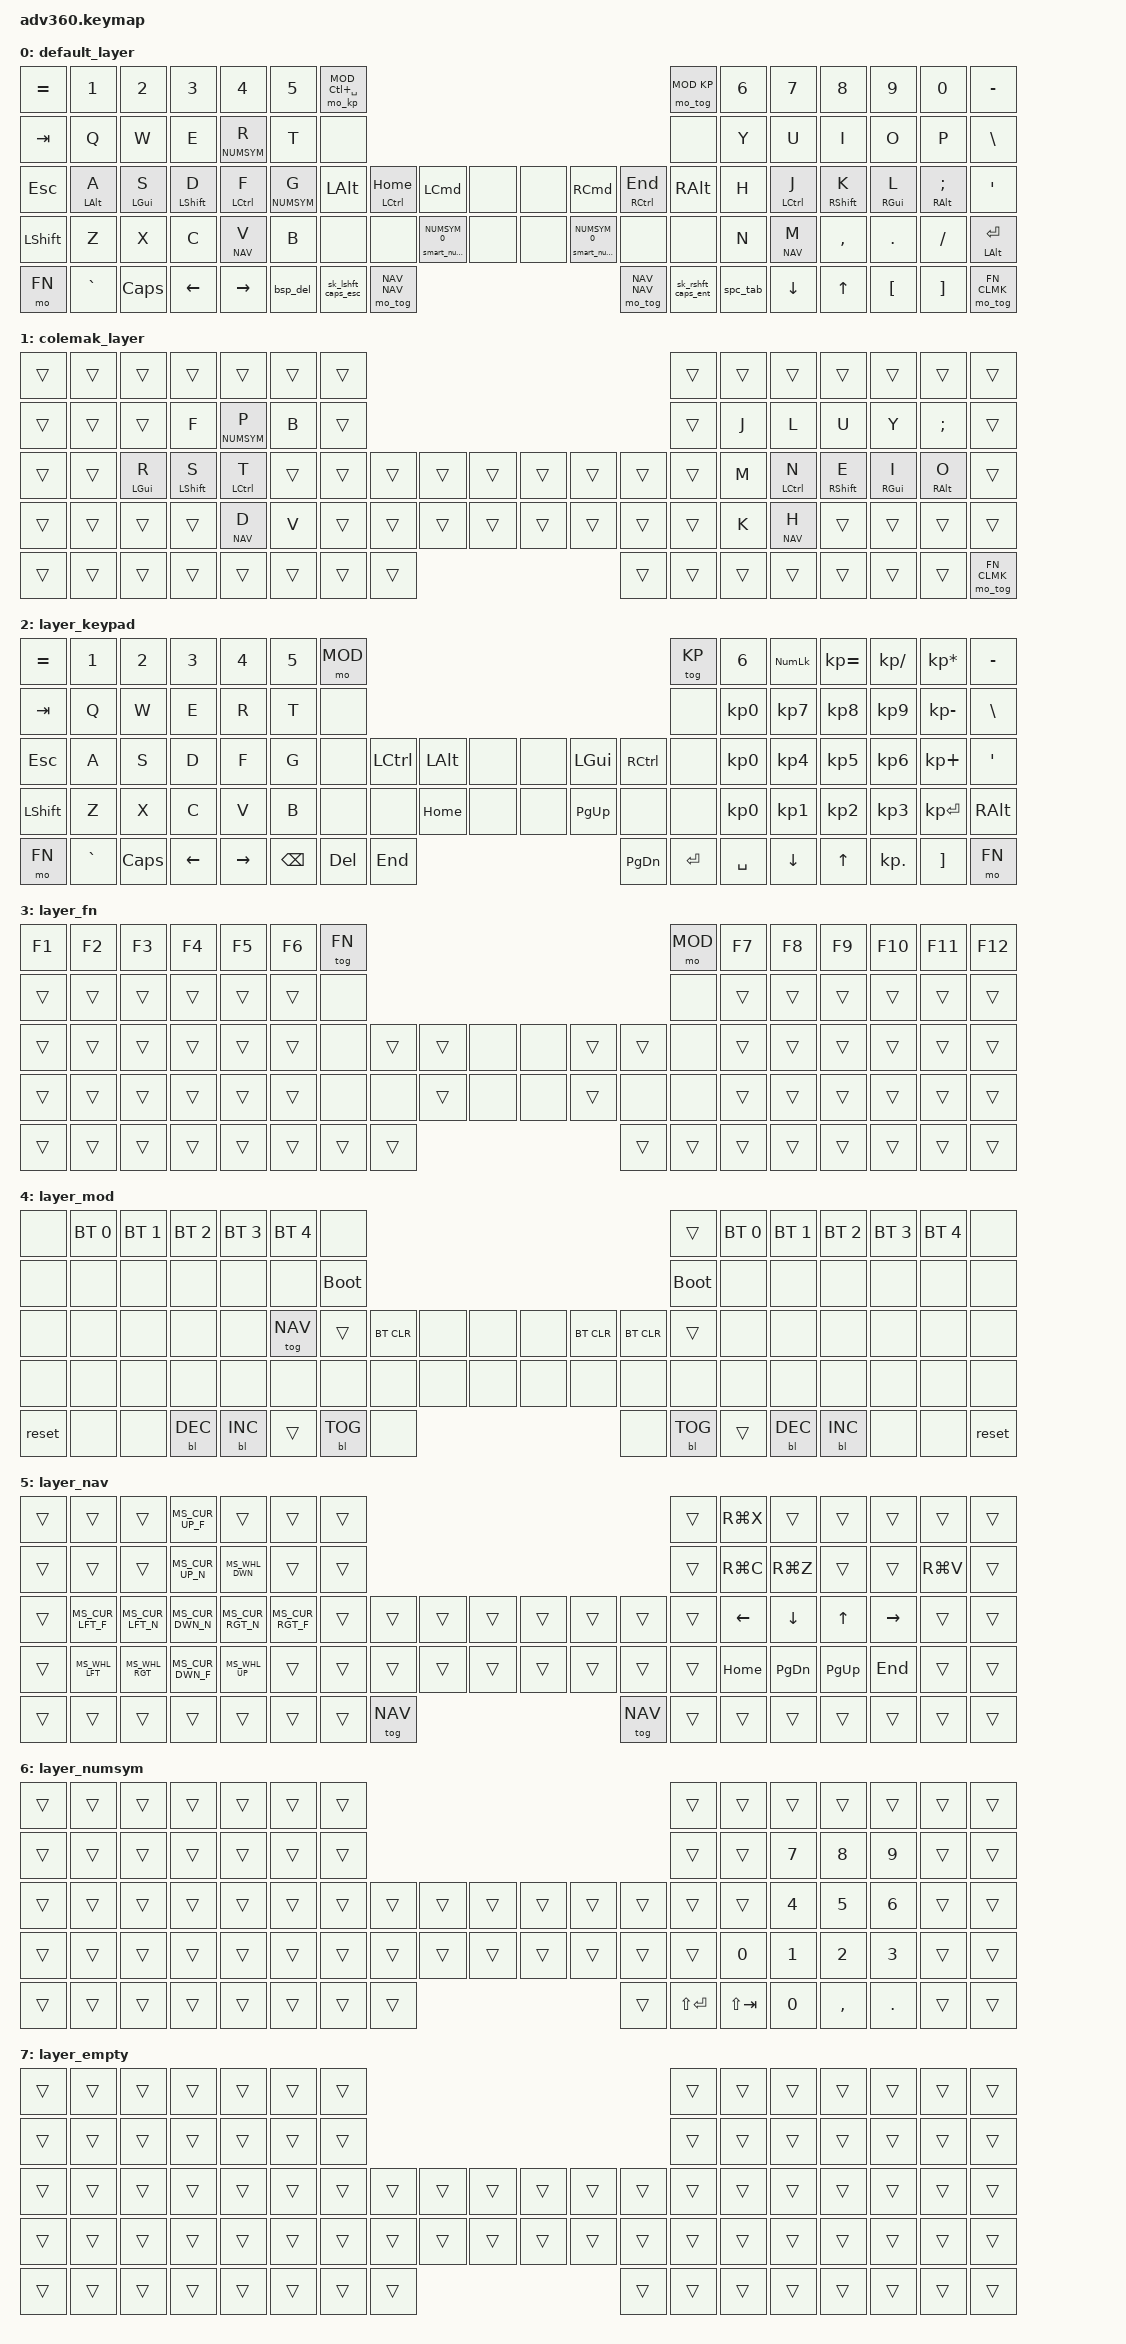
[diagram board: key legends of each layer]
#include <behaviors.dtsi>
#include <dt-bindings/zmk/keys.h>
#include <dt-bindings/zmk/bt.h>
#include <dt-bindings/zmk/outputs.h>
#include <dt-bindings/zmk/rgb.h>
#include <dt-bindings/zmk/backlight.h>

#include "./zmk-nodefree-config/helper.h"

/* definitions for mouse layer */
#include "mouse.dtsi"
 
#include "keypos_adv360.h"

#define KEYS_L LT0 LT1 LT2 LT3 LT4 LM0 LM1 LM2 LM3 LM4 LB0 LB1 LB2 LB3 LB4 LU0 LU1 LU2 LU3 // left-hand keys
#define KEYS_R RT0 RT1 RT2 RT3 RT4 RM0 RM1 RM2 RM3 RM4 RB0 RB1 RB2 RB3 RB4 RU0 RU1 RU2 RU3 // right-hand keys
#define THUMBS LH1 LH0 RH0 RH1                                       // thumb keys

#define QUICK_TAP_MS 175

ZMK_BEHAVIOR(hml, hold_tap,  // left-hand HRMs
    flavor = "balanced";
    tapping-term-ms = <280>;
    quick-tap-ms = <QUICK_TAP_MS>;
    global-quick-tap-ms = <150>;        // requires PR #1387
    bindings = <&kp>, <&kp>;
    hold-trigger-key-positions = <KEYS_R THUMBS>;
    hold-trigger-on-release;            // requires PR #1423
)

// here we use tap-unless-interrupted and not balanced because these are used for arrow keys and I want autorepeat of the arrow after waitig a while
// so the key is considered an wrrow key after the tapping-term-ms
ZMK_BEHAVIOR(hmr, hold_tap,  // right-hand HRMs
    flavor = "tap-unless-interrupted";
    tapping-term-ms = <650>;
    quick-tap-ms = <QUICK_TAP_MS>;
    global-quick-tap-ms = <150>;        // requires PR #1387
    bindings = <&kp>, <&kp>;
    hold-trigger-key-positions = <KEYS_L THUMBS>;
    hold-trigger-on-release;            // requires PR #1423
)

// replicate left-hand HRM for repeat combo
ZMK_BEHAVIOR(hml_repeat, hold_tap,
    flavor = "balanced";
    tapping-term-ms = <280>;
    quick-tap-ms = <QUICK_TAP_MS>;
    global-quick-tap-ms = <150>;
    bindings = <&kp>, <&key_repeat>;
    hold-trigger-key-positions = <KEYS_R THUMBS>;
    hold-trigger-on-release;
)

// replicate left-hand HRM for momentary layer
ZMK_BEHAVIOR(hml_ml, hold_tap,
    flavor = "balanced";
    tapping-term-ms = <280>;
    quick-tap-ms = <QUICK_TAP_MS>;
    global-quick-tap-ms = <150>;
    bindings = <&mo>, <&kp>;
    hold-trigger-key-positions = <KEYS_R THUMBS>; //?
    hold-trigger-on-release; //?
)

// replicate left-hand HRM for momentary layer
ZMK_BEHAVIOR(hmr_ml, hold_tap,
    flavor = "balanced";
    tapping-term-ms = <280>;
    quick-tap-ms = <QUICK_TAP_MS>;
    global-quick-tap-ms = <150>;
    bindings = <&mo>, <&kp>;
    hold-trigger-key-positions = <KEYS_L THUMBS>; //?
    hold-trigger-on-release; //?
)

#define ___ &trans
#define xxx &none

#define DEF 0
#define CLMK 1
#define KP 2
#define FN 3
#define MOD 4
#define NAV 5
#define NUMSYM 6

#define COMBO_SLOW 50
#define COMBO_NORM 35
#define COMBO_FAST 20

/* Sticky key settings ****************************************/ 
&sk {  // sticky-key config
    release-after-ms = <600>;  // release after 0.6s
    quick-release;             // no double capitalization when rolling keys
};

/* Sticky layer settings ****************************************/ 
&sl {
    release-after-ms = <7500>;
};

/* Caps word and Num word functionality *************************************************/ 
&caps_word {
    continue-list = <UNDERSCORE MINUS BSPC DEL>;
};

&num_word {
    layers = <NUMSYM>;
    continue-list = <BACKSPACE DELETE DOT COMMA DEL MINUS>;
};

ZMK_BEHAVIOR(smart_num_layer, hold_tap,
    tapping-term-ms = <200>;
    bindings = <&mo &num_word>;
)

#define SMART_NUM &smart_num_layer NUMSYM 0

/* Symbols Combos ****************************************/ 
#define TWOK_COMBO(name, keypos, bind_key, timeout) \
    ZMK_COMBO(name, &kp bind_key, keypos (keypos+1), ALL, timeout)

#define TWOK_COMBOEX(name, keypos, bindings, timeout) \
    ZMK_COMBO(name, bindings, keypos (keypos+1), ALL, timeout)
 
#define THREEK_COMBOEX(name, keypos, bindings, timeout) \
    ZMK_COMBO(name, bindings, keypos (keypos+1) (keypos+2), ALL, timeout)

#define TWOK_COMBO_SHIFTED(name, key_pos, base_key, shifted_key, timeout) \
    TWOK_COMBOEX(name, key_pos, &name, timeout) \
    ZMK_BEHAVIOR(name, mod_morph, \
        bindings = <&kp base_key>, <&kp shifted_key>; \
        mods = <(MOD_LSFT|MOD_RSFT)>; \
    )
 
#define TWOK_COMBOEX_SHIFTED(name, key_pos, base_bind, shifted_bind, timeout) \
    TWOK_COMBOEX(name, key_pos, &name, timeout) \
    ZMK_BEHAVIOR(name, mod_morph, \
        bindings = <&base_bind>, <&shifted_bind>; \
        mods = <(MOD_LSFT|MOD_RSFT)>; \
    )

TWOK_COMBO_SHIFTED(ampersand_pipe, 42, AMPS, CARET, COMBO_NORM)
TWOK_COMBO_SHIFTED(hash_dollar, 17, HASH, DOLLAR, COMBO_NORM)
TWOK_COMBO_SHIFTED(equal_percent, 31, EQUAL, PERCENT, COMBO_NORM)
TWOK_COMBO_SHIFTED(under_pipe, 63, UNDER, PIPE, COMBO_NORM)
TWOK_COMBO_SHIFTED(minus_plus, 30, MINUS, PLUS, COMBO_NORM)
TWOK_COMBO_SHIFTED(quote_dblquote, 64, SQT, DQT, COMBO_NORM)
TWOK_COMBO_SHIFTED(exclamation_atsign, 16, EXCLAMATION, AT_SIGN, COMBO_NORM)
TWOK_COMBO_SHIFTED(grave_tilde, 50, GRAVE, TILDE, COMBO_NORM)
TWOK_COMBO_SHIFTED(backslash_asterisk, 51, BACKSLASH, ASTRK, COMBO_NORM)

/* Two colons with shifter semicolon combo **************************************** */
TWOK_COMBOEX(combo_two_colons, 45, &two_colons_semi , COMBO_NORM)
ZMK_BEHAVIOR(two_colons, macro,
    bindings = <&macro_tap &kp COLON &kp COLON>;
)
ZMK_BEHAVIOR(two_colons_semi, mod_morph,
    bindings = <&two_colons>, <&kp GRAVE>; // using grave to get semicolon in hebrew
    mods = <(MOD_LSFT|MOD_RSFT)>;
)

/* Two key combo greater/less than with brackets **************************************** */ 
TWOK_COMBO_SHIFTED(lt_lbkt, 23, LT, LBKT, COMBO_NORM)
TWOK_COMBO_SHIFTED(gt_rbkt, 24, GT, RBKT, COMBO_NORM)

/* Three key combo greater/less than with brackets **************************************** */ 
THREEK_COMBOEX(combo_both_gtlt_brackets, 23, &both_gtlt_brackets, COMBO_NORM)
ZMK_BEHAVIOR(both_gtlt_brackets, mod_morph,
    bindings = <&macro_both_gtlt>, <&macro_both_brackets>;
    mods = <(MOD_LSFT|MOD_RSFT)>;
)
ZMK_BEHAVIOR(macro_both_gtlt, macro,
    bindings = <&macro_tap &kp LT &kp GT>;
)
ZMK_BEHAVIOR(macro_both_brackets, macro,
    bindings = <&macro_tap &kp LBKT &kp RBKT>;
)

/* Two key combo parenthesis with braces **************************************** */ 
TWOK_COMBO_SHIFTED(left_parenthesis_brace, 43, LPAR, LBRC, COMBO_FAST)
TWOK_COMBO_SHIFTED(right_parenthesis_brace, 44, RPAR, RBRC, COMBO_NORM)

/* Three key parenthesis with braces **************************************** */
THREEK_COMBOEX(combo_both_parenthesis, 43, &both_parenthesis_braces, COMBO_NORM)
ZMK_BEHAVIOR(both_parenthesis_braces, mod_morph,
    bindings = <&macro_both_parenthesis>, <&macro_both_braces>;
    mods = <(MOD_LSFT|MOD_RSFT)>;
)
ZMK_BEHAVIOR(macro_both_parenthesis, macro,
    bindings = <&macro_tap &kp LPAR &kp RPAR>;
)
ZMK_BEHAVIOR(macro_both_braces, macro,
    bindings = <&macro_tap &kp LBRC &kp RBRC>;
)
 
/* Three key '--' **************************************** */
THREEK_COMBOEX(combo_double_minus, 30, &double_minus_double_plus, COMBO_NORM)
ZMK_BEHAVIOR(double_minus_double_plus, mod_morph,
    bindings = <&macro_double_minus>, <&macro_double_plus>;
    mods = <(MOD_LSFT|MOD_RSFT)>;
)
ZMK_BEHAVIOR(macro_double_minus, macro,
    bindings = <&macro_tap &kp KP_MINUS &kp KP_MINUS>;
)
ZMK_BEHAVIOR(macro_double_plus, macro,
    bindings = <&macro_tap &kp EQUAL &kp EQUAL>;
)
// ZMK_BEHAVIOR(unshifted_tab, macro,
//     bindings = <&macro_release &kp LSHIFT>, <&macro_tap &kp TAB>, <&macro_press &kp LSHIFT>;
// )

/* New Behaviors */

ZMK_BEHAVIOR(mo_tog, hold_tap,
    flavor = "hold-preferred";
    tapping-term-ms = <200>;
    bindings = <&mo>, <&tog>;
)

ZMK_BEHAVIOR(mo_sl, hold_tap,
    flavor = "hold-preferred";
    tapping-term-ms = <200>;
    bindings = <&mo>, <&sl>;
)

ZMK_BEHAVIOR(mo_kp, hold_tap,
    flavor = "hold-preferred";
    tapping-term-ms = <200>;
    bindings = <&mo>, <&kp>;
)

ZMK_BEHAVIOR(skq, sticky_key,
    bindings = <&kp>;
    release-after-ms = <1000>;
    quick-release;
)

/* Specific Keys */

ZMK_BEHAVIOR(spc_tab, mod_morph,
        bindings = <&kp SPACE>, <&kp TAB>;
        mods = <(MOD_LSFT)>;
        keep-mods = <0>;
)

// hold: right-shift | tap: sticky shift | left-shift+tap: enter | double-tap: caps_word | triple-tap: cancel
ZMK_BEHAVIOR(sk_rshft_caps_td, tap_dance,
    tapping-term-ms = <250>;
    bindings = <&skq RSHIFT>, <&caps_word>, <&kp K_CANCEL>;
)
ZMK_BEHAVIOR(sk_rshft_caps_ent, mod_morph,
        bindings = <&sk_rshft_caps_td>, <&kp ENTER>;
        mods = <(MOD_LSFT)>; // On purpose only left shift to avoid critical mistakes between space and enter
        keep-mods = <0>;
)

// hold: left-shift | tap: sticky shift | right-shift+tap: esc | double-tap: caps_word | triple-tap: cancel
ZMK_BEHAVIOR(sk_lshft_caps_td, tap_dance,
    tapping-term-ms = <250>;
    bindings = <&skq LSHIFT>, <&caps_word>, <&kp K_CANCEL>;
)

ZMK_BEHAVIOR(sk_lshft_caps_esc, mod_morph,
        bindings = <&sk_lshft_caps_td>, <&kp ESC>;
        mods = <(MOD_RSFT)>; // On purpose only right shift
        keep-mods = <0>;
)

// tap: backspace | shift-tap: delete
ZMK_BEHAVIOR(bsp_del, mod_morph,
        bindings = <&kp BSPC>, <&kp DEL>;
        mods = <(MOD_RSFT|MOD_LSFT)>;
        keep-mods = <0>;
)

// Next two combos prevent the K (which is the shift) from autorepeating making it unusable
// shift-enter - for some reasone requires pressing first enter than the home row shift
// ZMK_COMBO(shift_enter, &kp LS(ENTER), 74 77 44, ALL, 10000)

// shift-enter - for some reasone requires pressing first enter than the home row shift
// ZMK_COMBO(shift_tab, &kp LS(TAB), 74 78 44, ALL, 10000)

// Change language using both left and right shift thumbs together
// ZMK_COMBO(thumbs_change_lang, &kp LG(Q), 74 77, ALL, COMBO_SLOW)

// tests in context of checking issues with combo not interruting tap-dance
//
// ZMK_BEHAVIOR(test_tap_dance, tap_dance,
//     tapping-term-ms = <3000>;
//     bindings = <&kp A>, <&kp B>;
// )
//
// ZMK_BEHAVIOR(test_hold_tap, hold_tap,
//     flavor = "hold-preferred";
//     tapping-term-ms = <200>;
//     bindings = <&kp>, <&kp>;
// )
// TWOK_COMBOEX(combo_test, 79, &kp C , COMBO_NORM)
//
// / {
//     combos {
//         compatible = "zmk,combos";
//         combo_test2 {
//             timeout-ms = <50>;
//             key-positions = <81 82>;
//             bindings = <&kp E>;
//         };
//     };
// };

ZMK_LAYER(default_layer,
//╭─────────────────┬─────────────────┬─────────────────┬─────────────────┬─────────────────┬─────────────────┬─────────────────┬─────────────────┬─────────────────╮╭─────╮ ╭─────╮╭─────────────────┬─────────────────┬─────────────────┬─────────────────┬─────────────────┬─────────────────┬─────────────────┬─────────────────┬─────────────────╮
   &kp EQUAL         &kp N1            &kp N2            &kp N3            &kp N4            &kp N5          &mo_kp MOD LC(SPACE)                                                                                        &mo_tog MOD KP    &kp N6            &kp N7            &kp N8            &kp N9            &kp N0            &kp MINUS
//├─────────────────┼─────────────────┼─────────────────┼─────────────────┼─────────────────┼─────────────────┼─────────────────┼─────────────────┼─────────────────┤├─────┤ ├─────┤├─────────────────┼─────────────────┼─────────────────┼─────────────────┼─────────────────┼─────────────────┼─────────────────┼─────────────────┼─────────────────┤
   &kp TAB           &kp Q             &kp W             &kp E             &hml_ml NUMSYM R  &kp T             &none                                                                                                     &none             &kp Y             &kp U             &kp I             &kp O             &kp P             &kp BSLH
//├─────────────────┼─────────────────┼─────────────────┼─────────────────┼─────────────────┼─────────────────┼─────────────────┼─────────────────┼─────────────────┤├─────┤ ├─────┤├─────────────────┼─────────────────┼─────────────────┼─────────────────┼─────────────────┼─────────────────┼─────────────────┼─────────────────┼─────────────────┤
   &kp ESC           &hml LALT A       &hml LGUI S       &hml LSHFT D      &hml LCTRL F      &hml_ml NUMSYM G  &kp LALT          &mt LCTRL HOME    &kp LCMD           &none   &none  &kp RCMD          &mt RCTRL END     &kp RALT          &kp H             &hmr LCTRL J      &hmr RSHFT K      &hmr RGUI L       &hmr RALT SEMI    &kp SQT
//├─────────────────┼─────────────────┼─────────────────┼─────────────────┼─────────────────┼─────────────────┼─────────────────┼─────────────────┼─────────────────┤├─────┤ ├─────┤├─────────────────┼─────────────────┼─────────────────┼─────────────────┼─────────────────┼─────────────────┼─────────────────┼─────────────────┼─────────────────┤
   &kp LSHFT         &kp Z             &kp X             &kp C             &hml_ml NAV V     &kp B             xxx               xxx               SMART_NUM          &none   &none  SMART_NUM         xxx               xxx               &kp N             &hmr_ml NAV M     &kp COMMA         &kp DOT           &kp FSLH          &mt LALT ENTER
//├─────────────────┼─────────────────┼─────────────────┼─────────────────┼─────────────────┼─────────────────┼─────────────────┼─────────────────┼─────────────────┤├─────┤ ├─────┤├─────────────────┼─────────────────┼─────────────────┼─────────────────┼─────────────────┼─────────────────┼─────────────────┼─────────────────┼─────────────────┤
   &mo FN            &kp GRAVE         &kp CAPS          &kp LEFT          &kp RIGHT                           &bsp_del         &sk_lshft_caps_esc &mo_tog NAV NAV                   &mo_tog NAV NAV  &sk_rshft_caps_ent &spc_tab                            &kp DOWN          &kp UP            &kp LBKT          &kp RBKT          &mo_tog FN CLMK
//╰─────────────────┴─────────────────┴─────────────────┴─────────────────┴─────────────────┴─────────────────┴─────────────────┴─────────────────┴─────────────────╯╰─────╯ ╰─────╯╰─────────────────┴─────────────────┴─────────────────┴─────────────────┴─────────────────┴─────────────────┴─────────────────┴─────────────────┴─────────────────╯
)

ZMK_LAYER(colemak_layer,
//╭─────────────────┬─────────────────┬─────────────────┬─────────────────┬─────────────────┬─────────────────┬─────────────────┬─────────────────┬─────────────────╮╭─────╮ ╭─────╮╭─────────────────┬─────────────────┬─────────────────┬─────────────────┬─────────────────┬─────────────────┬─────────────────┬─────────────────┬─────────────────╮
   ___               ___               ___               ___               ___               ___               ___                                                                                                       ___               ___               ___               ___               ___               ___               ___   
//├─────────────────┼─────────────────┼─────────────────┼─────────────────┼─────────────────┼─────────────────┼─────────────────┼─────────────────┼─────────────────┤├─────┤ ├─────┤├─────────────────┼─────────────────┼─────────────────┼─────────────────┼─────────────────┼─────────────────┼─────────────────┼─────────────────┼─────────────────┤
   ___               ___               ___               &kp F             &hml_ml NUMSYM P  &kp B             ___                                                                                                       ___               &kp J             &kp L             &kp U             &kp Y             &kp SEMI          ___   
//├─────────────────┼─────────────────┼─────────────────┼─────────────────┼─────────────────┼─────────────────┼─────────────────┼─────────────────┼─────────────────┤├─────┤ ├─────┤├─────────────────┼─────────────────┼─────────────────┼─────────────────┼─────────────────┼─────────────────┼─────────────────┼─────────────────┼─────────────────┤
   ___               ___               &hml LGUI R       &hml LSHFT S      &hml LCTRL T      ___               ___               ___               ___                ___     ___    ___               ___               ___               &kp M             &hmr LCTRL N      &hmr RSHFT E      &hmr RGUI I       &hmr RALT O       ___   
//├─────────────────┼─────────────────┼─────────────────┼─────────────────┼─────────────────┼─────────────────┼─────────────────┼─────────────────┼─────────────────┤├─────┤ ├─────┤├─────────────────┼─────────────────┼─────────────────┼─────────────────┼─────────────────┼─────────────────┼─────────────────┼─────────────────┼─────────────────┤
   ___               ___               ___               ___               &hml_ml NAV D     &kp V             ___               ___               ___                ___     ___    ___               ___               ___               &kp K             &hmr_ml NAV H     ___               ___               ___               ___   
//├─────────────────┼─────────────────┼─────────────────┼─────────────────┼─────────────────┼─────────────────┼─────────────────┼─────────────────┼─────────────────┤├─────┤ ├─────┤├─────────────────┼─────────────────┼─────────────────┼─────────────────┼─────────────────┼─────────────────┼─────────────────┼─────────────────┼─────────────────┤
   ___               ___               ___               ___               ___                                 ___               ___               ___                               ___               ___               ___                                 ___               ___               ___               ___               &mo_tog FN CLMK   
//╰─────────────────┴─────────────────┴─────────────────┴─────────────────┴─────────────────┴─────────────────┴─────────────────┴─────────────────┴─────────────────╯╰─────╯ ╰─────╯╰─────────────────┴─────────────────┴─────────────────┴─────────────────┴─────────────────┴─────────────────┴─────────────────┴─────────────────┴─────────────────╯
)

ZMK_LAYER(layer_keypad,
//╭─────────────────┬─────────────────┬─────────────────┬─────────────────┬─────────────────┬─────────────────┬─────────────────┬─────────────────┬─────────────────╮╭─────╮ ╭─────╮╭─────────────────┬─────────────────┬─────────────────┬─────────────────┬─────────────────┬─────────────────┬─────────────────┬─────────────────┬─────────────────╮
   &kp EQUAL         &kp N1            &kp N2            &kp N3            &kp N4            &kp N5            &mo MOD                                                                                                   &tog KP           &kp N6            &kp KP_NUM        &kp KP_EQUAL      &kp KP_DIVIDE     &kp KP_MULTIPLY   &kp MINUS
//├─────────────────┼─────────────────┼─────────────────┼─────────────────┼─────────────────┼─────────────────┼─────────────────┼─────────────────┼─────────────────┤├─────┤ ├─────┤├─────────────────┼─────────────────┼─────────────────┼─────────────────┼─────────────────┼─────────────────┼─────────────────┼─────────────────┼─────────────────┤
   &kp TAB           &kp Q             &kp W             &kp E             &kp R             &kp T             &none                                                                                                     &none             &kp KP_N0         &kp KP_N7         &kp KP_N8         &kp KP_N9         &kp KP_MINUS      &kp BSLH
//├─────────────────┼─────────────────┼─────────────────┼─────────────────┼─────────────────┼─────────────────┼─────────────────┼─────────────────┼─────────────────┤├─────┤ ├─────┤├─────────────────┼─────────────────┼─────────────────┼─────────────────┼─────────────────┼─────────────────┼─────────────────┼─────────────────┼─────────────────┤
   &kp ESC           &kp A             &kp S             &kp D             &kp F             &kp G             &none             &kp LCTRL         &kp LALT           &none   &none  &kp LGUI          &kp RCTRL         &none             &kp KP_N0         &kp KP_N4         &kp KP_N5         &kp KP_N6         &kp KP_PLUS       &kp SQT
//├─────────────────┼─────────────────┼─────────────────┼─────────────────┼─────────────────┼─────────────────┼─────────────────┼─────────────────┼─────────────────┤├─────┤ ├─────┤├─────────────────┼─────────────────┼─────────────────┼─────────────────┼─────────────────┼─────────────────┼─────────────────┼─────────────────┼─────────────────┤
   &kp LSHFT         &kp Z             &kp X             &kp C             &kp V             &kp B             &none             &none             &kp HOME           &none   &none  &kp PG_UP         &none             &none             &kp KP_N0         &kp KP_N1         &kp KP_N2         &kp KP_N3         &kp KP_ENTER      &kp RALT
//├─────────────────┼─────────────────┼─────────────────┼─────────────────┼─────────────────┼─────────────────┼─────────────────┼─────────────────┼─────────────────┤├─────┤ ├─────┤├─────────────────┼─────────────────┼─────────────────┼─────────────────┼─────────────────┼─────────────────┼─────────────────┼─────────────────┼─────────────────┤
   &mo FN            &kp GRAVE         &kp CAPS          &kp LEFT          &kp RIGHT                           &kp BSPC          &kp DEL           &kp END                           &kp PG_DN         &kp ENTER         &kp SPACE                           &kp DOWN          &kp UP            &kp KP_DOT        &kp RBKT          &mo FN
//╰─────────────────┴─────────────────┴─────────────────┴─────────────────┴─────────────────┴─────────────────┴─────────────────┴─────────────────┴─────────────────╯╰─────╯ ╰─────╯╰─────────────────┴─────────────────┴─────────────────┴─────────────────┴─────────────────┴─────────────────┴─────────────────┴─────────────────┴─────────────────╯
)

ZMK_LAYER(layer_fn,
//╭─────────────────┬─────────────────┬─────────────────┬─────────────────┬─────────────────┬─────────────────┬─────────────────┬─────────────────┬─────────────────╮╭─────╮ ╭─────╮╭─────────────────┬─────────────────┬─────────────────┬─────────────────┬─────────────────┬─────────────────┬─────────────────┬─────────────────┬─────────────────╮
   &kp F1            &kp F2            &kp F3            &kp F4            &kp F5            &kp F6            &tog FN                                                                                                   &mo MOD           &kp F7            &kp F8            &kp F9            &kp F10           &kp F11           &kp F12
//├─────────────────┼─────────────────┼─────────────────┼─────────────────┼─────────────────┼─────────────────┼─────────────────┼─────────────────┼─────────────────┤├─────┤ ├─────┤├─────────────────┼─────────────────┼─────────────────┼─────────────────┼─────────────────┼─────────────────┼─────────────────┼─────────────────┼─────────────────┤
   ___               ___               ___               ___               ___               ___               &none                                                                                                     &none             ___               ___               ___               ___               ___               ___   
//├─────────────────┼─────────────────┼─────────────────┼─────────────────┼─────────────────┼─────────────────┼─────────────────┼─────────────────┼─────────────────┤├─────┤ ├─────┤├─────────────────┼─────────────────┼─────────────────┼─────────────────┼─────────────────┼─────────────────┼─────────────────┼─────────────────┼─────────────────┤
   ___               ___               ___               ___               ___               ___               &none             ___               ___                &none   &none  ___               ___               &none             ___               ___               ___               ___               ___               ___   
//├─────────────────┼─────────────────┼─────────────────┼─────────────────┼─────────────────┼─────────────────┼─────────────────┼─────────────────┼─────────────────┤├─────┤ ├─────┤├─────────────────┼─────────────────┼─────────────────┼─────────────────┼─────────────────┼─────────────────┼─────────────────┼─────────────────┼─────────────────┤
   ___               ___               ___               ___               ___               ___               &none             &none             ___                &none   &none  ___               &none             &none             ___               ___               ___               ___               ___               ___   
//├─────────────────┼─────────────────┼─────────────────┼─────────────────┼─────────────────┼─────────────────┼─────────────────┼─────────────────┼─────────────────┤├─────┤ ├─────┤├─────────────────┼─────────────────┼─────────────────┼─────────────────┼─────────────────┼─────────────────┼─────────────────┼─────────────────┼─────────────────┤
   ___               ___               ___               ___               ___                                 ___               ___               ___                               ___               ___               ___                                 ___               ___               ___               ___               ___   
//╰─────────────────┴─────────────────┴─────────────────┴─────────────────┴─────────────────┴─────────────────┴─────────────────┴─────────────────┴─────────────────╯╰─────╯ ╰─────╯╰─────────────────┴─────────────────┴─────────────────┴─────────────────┴─────────────────┴─────────────────┴─────────────────┴─────────────────┴─────────────────╯
)

ZMK_LAYER(layer_mod,
//╭─────────────────┬─────────────────┬─────────────────┬─────────────────┬─────────────────┬─────────────────┬─────────────────┬─────────────────┬─────────────────╮╭─────╮ ╭─────╮╭─────────────────┬─────────────────┬─────────────────┬─────────────────┬─────────────────┬─────────────────┬─────────────────┬─────────────────┬─────────────────╮
   &none             &bt BT_SEL 0      &bt BT_SEL 1      &bt BT_SEL 2      &bt BT_SEL 3      &bt BT_SEL 4      &none                                                                                                     ___               &bt BT_SEL 0      &bt BT_SEL 1      &bt BT_SEL 2      &bt BT_SEL 3      &bt BT_SEL 4      &none
//├─────────────────┼─────────────────┼─────────────────┼─────────────────┼─────────────────┼─────────────────┼─────────────────┼─────────────────┼─────────────────┤├─────┤ ├─────┤├─────────────────┼─────────────────┼─────────────────┼─────────────────┼─────────────────┼─────────────────┼─────────────────┼─────────────────┼─────────────────┤
   &none             &none             &none             &none             &none             &none             &bootloader                                                                                               &bootloader       &none             &none             &none             &none             &none             &none
//├─────────────────┼─────────────────┼─────────────────┼─────────────────┼─────────────────┼─────────────────┼─────────────────┼─────────────────┼─────────────────┤├─────┤ ├─────┤├─────────────────┼─────────────────┼─────────────────┼─────────────────┼─────────────────┼─────────────────┼─────────────────┼─────────────────┼─────────────────┤
   &none             &none             &none             &none             &none             &tog NAV          ___               &bt BT_CLR        &none              &none   &none  &bt BT_CLR        &bt BT_CLR        ___               &none             &none             &none             &none             &none             &none
 //&none             &none             &none             &none             &none             &tog NAV     &rgb_ug RGB_MEFS_CMD 5 &bt BT_CLR        &none              &none   &none  &bt BT_CLR        &bt BT_CLR   &rgb_ug RGB_MEFS_CMD 5 &none             &none             &none             &none             &none             &none
//├─────────────────┼─────────────────┼─────────────────┼─────────────────┼─────────────────┼─────────────────┼─────────────────┼─────────────────┼─────────────────┤├─────┤ ├─────┤├─────────────────┼─────────────────┼─────────────────┼─────────────────┼─────────────────┼─────────────────┼─────────────────┼─────────────────┼─────────────────┤
   &none             &none             &none             &none             &none             &none             &none             &none             &none              &none   &none  &none             &none             &none             &none             &none             &none             &none             &none             &none
//├─────────────────┼─────────────────┼─────────────────┼─────────────────┼─────────────────┼─────────────────┼─────────────────┼─────────────────┼─────────────────┤├─────┤ ├─────┤├─────────────────┼─────────────────┼─────────────────┼─────────────────┼─────────────────┼─────────────────┼─────────────────┼─────────────────┼─────────────────┤
   &reset            &none             &none             &bl BL_DEC        &bl BL_INC                          ___               &bl BL_TOG        &none                             &none             &bl BL_TOG        ___                                 &bl BL_DEC        &bl BL_INC        &none             &none             &reset
// &none             &none             &none             &bl BL_DEC        &bl BL_INC                          &rgb_ug RGB_TOG   &bl BL_TOG        &none                             &none             &bl BL_TOG        &rgb_ug RGB_TOG                     &bl BL_DEC        &bl BL_INC        &none             &none             &none 
//╰─────────────────┴─────────────────┴─────────────────┴─────────────────┴─────────────────┴─────────────────┴─────────────────┴─────────────────┴─────────────────╯╰─────╯ ╰─────╯╰─────────────────┴─────────────────┴─────────────────┴─────────────────┴─────────────────┴─────────────────┴─────────────────┴─────────────────┴─────────────────╯
)

ZMK_LAYER(layer_nav,
//╭─────────────────┬─────────────────┬─────────────────┬─────────────────┬─────────────────┬─────────────────┬─────────────────┬─────────────────┬─────────────────╮╭─────╮ ╭─────╮╭─────────────────┬─────────────────┬─────────────────┬─────────────────┬─────────────────┬─────────────────┬─────────────────┬─────────────────┬─────────────────╮
   ___               ___               ___               MS_CUR_UP_F       ___               ___               ___                                                                                                       ___               &kp RG(X)         ___               ___               ___               ___               ___   
//├─────────────────┼─────────────────┼─────────────────┼─────────────────┼─────────────────┼─────────────────┼─────────────────┼─────────────────┼─────────────────┤├─────┤ ├─────┤├─────────────────┼─────────────────┼─────────────────┼─────────────────┼─────────────────┼─────────────────┼─────────────────┼─────────────────┼─────────────────┤
   ___               ___               ___               MS_CUR_UP_N       MS_WHL_DWN        ___               ___                                                                                                       ___               &kp RG(C)         &kp RG(Z)         ___               ___               &kp RG(V)         ___  
//├─────────────────┼─────────────────┼─────────────────┼─────────────────┼─────────────────┼─────────────────┼─────────────────┼─────────────────┼─────────────────┤├─────┤ ├─────┤├─────────────────┼─────────────────┼─────────────────┼─────────────────┼─────────────────┼─────────────────┼─────────────────┼─────────────────┼─────────────────┤
   ___               MS_CUR_LFT_F      MS_CUR_LFT_N      MS_CUR_DWN_N      MS_CUR_RGT_N      MS_CUR_RGT_F      ___               ___               ___                ___     ___    ___               ___               ___               &kp LEFT          &kp DOWN          &kp UP            &kp RIGHT         ___               ___   
//├─────────────────┼─────────────────┼─────────────────┼─────────────────┼─────────────────┼─────────────────┼─────────────────┼─────────────────┼─────────────────┤├─────┤ ├─────┤├─────────────────┼─────────────────┼─────────────────┼─────────────────┼─────────────────┼─────────────────┼─────────────────┼─────────────────┼─────────────────┤
   ___               MS_WHL_LFT        MS_WHL_RGT        MS_CUR_DWN_F      MS_WHL_UP         ___               ___               ___               ___                ___     ___    ___               ___               ___               &kp HOME          &kp PG_DN         &kp PG_UP         &kp END           ___               ___   
//├─────────────────┼─────────────────┼─────────────────┼─────────────────┼─────────────────┼─────────────────┼─────────────────┼─────────────────┼─────────────────┤├─────┤ ├─────┤├─────────────────┼─────────────────┼─────────────────┼─────────────────┼─────────────────┼─────────────────┼─────────────────┼─────────────────┼─────────────────┤
   ___               ___               ___               ___               ___                                 ___               ___               &tog NAV                          &tog NAV          ___               ___                                 ___               ___               ___               ___               ___   
//╰─────────────────┴─────────────────┴─────────────────┴─────────────────┴─────────────────┴─────────────────┴─────────────────┴─────────────────┴─────────────────╯╰─────╯ ╰─────╯╰─────────────────┴─────────────────┴─────────────────┴─────────────────┴─────────────────┴─────────────────┴─────────────────┴─────────────────┴─────────────────╯
)

ZMK_LAYER(layer_numsym,
//╭─────────────────┬─────────────────┬─────────────────┬─────────────────┬─────────────────┬─────────────────┬─────────────────┬─────────────────┬─────────────────╮╭─────╮ ╭─────╮╭─────────────────┬─────────────────┬─────────────────┬─────────────────┬─────────────────┬─────────────────┬─────────────────┬─────────────────┬─────────────────╮
   ___               ___               ___               ___               ___               ___               ___                                                                                                       ___               ___               ___               ___               ___               ___               ___   
//├─────────────────┼─────────────────┼─────────────────┼─────────────────┼─────────────────┼─────────────────┼─────────────────┼─────────────────┼─────────────────┤├─────┤ ├─────┤├─────────────────┼─────────────────┼─────────────────┼─────────────────┼─────────────────┼─────────────────┼─────────────────┼─────────────────┼─────────────────┤
   ___               ___               ___               ___               ___               ___               ___                                                                                                       ___               ___               &kp N7            &kp N8            &kp N9            ___               ___ 
//├─────────────────┼─────────────────┼─────────────────┼─────────────────┼─────────────────┼─────────────────┼─────────────────┼─────────────────┼─────────────────┤├─────┤ ├─────┤├─────────────────┼─────────────────┼─────────────────┼─────────────────┼─────────────────┼─────────────────┼─────────────────┼─────────────────┼─────────────────┤
   ___               ___               ___               ___               ___               ___               ___               ___               ___                ___     ___    ___               ___               ___               ___               &kp N4            &kp N5            &kp N6            ___               ___    
//├─────────────────┼─────────────────┼─────────────────┼─────────────────┼─────────────────┼─────────────────┼─────────────────┼─────────────────┼─────────────────┤├─────┤ ├─────┤├─────────────────┼─────────────────┼─────────────────┼─────────────────┼─────────────────┼─────────────────┼─────────────────┼─────────────────┼─────────────────┤
   ___               ___               ___               ___               ___               ___               ___               ___               ___                ___     ___    ___               ___               ___               &kp N0            &kp N1            &kp N2            &kp N3            ___               ___   
//├─────────────────┼─────────────────┼─────────────────┼─────────────────┼─────────────────┼─────────────────┼─────────────────┼─────────────────┼─────────────────┤├─────┤ ├─────┤├─────────────────┼─────────────────┼─────────────────┼─────────────────┼─────────────────┼─────────────────┼─────────────────┼─────────────────┼─────────────────┤
   ___               ___               ___               ___               ___                                 ___               ___               ___                               ___               &kp LS(ENTER)     &kp LS(TAB)                         &kp N0            &kp COMMA         &kp DOT           ___               ___   
//╰─────────────────┴─────────────────┴─────────────────┴─────────────────┴─────────────────┴─────────────────┴─────────────────┴─────────────────┴─────────────────╯╰─────╯ ╰─────╯╰─────────────────┴─────────────────┴─────────────────┴─────────────────┴─────────────────┴─────────────────┴─────────────────┴─────────────────┴─────────────────╯
)

ZMK_LAYER(layer_empty,
//╭─────────────────┬─────────────────┬─────────────────┬─────────────────┬─────────────────┬─────────────────┬─────────────────┬─────────────────┬─────────────────╮╭─────╮ ╭─────╮╭─────────────────┬─────────────────┬─────────────────┬─────────────────┬─────────────────┬─────────────────┬─────────────────┬─────────────────┬─────────────────╮
   ___               ___               ___               ___               ___               ___               ___                                                                                                       ___               ___               ___               ___               ___               ___               ___   
//├─────────────────┼─────────────────┼─────────────────┼─────────────────┼─────────────────┼─────────────────┼─────────────────┼─────────────────┼─────────────────┤├─────┤ ├─────┤├─────────────────┼─────────────────┼─────────────────┼─────────────────┼─────────────────┼─────────────────┼─────────────────┼─────────────────┼─────────────────┤
   ___               ___               ___               ___               ___               ___               ___                                                                                                       ___               ___               ___               ___               ___               ___               ___   
//├─────────────────┼─────────────────┼─────────────────┼─────────────────┼─────────────────┼─────────────────┼─────────────────┼─────────────────┼─────────────────┤├─────┤ ├─────┤├─────────────────┼─────────────────┼─────────────────┼─────────────────┼─────────────────┼─────────────────┼─────────────────┼─────────────────┼─────────────────┤
   ___               ___               ___               ___               ___               ___               ___               ___               ___                ___     ___    ___               ___               ___               ___               ___               ___               ___               ___               ___   
//├─────────────────┼─────────────────┼─────────────────┼─────────────────┼─────────────────┼─────────────────┼─────────────────┼─────────────────┼─────────────────┤├─────┤ ├─────┤├─────────────────┼─────────────────┼─────────────────┼─────────────────┼─────────────────┼─────────────────┼─────────────────┼─────────────────┼─────────────────┤
   ___               ___               ___               ___               ___               ___               ___               ___               ___                ___     ___    ___               ___               ___               ___               ___               ___               ___               ___               ___   
//├─────────────────┼─────────────────┼─────────────────┼─────────────────┼─────────────────┼─────────────────┼─────────────────┼─────────────────┼─────────────────┤├─────┤ ├─────┤├─────────────────┼─────────────────┼─────────────────┼─────────────────┼─────────────────┼─────────────────┼─────────────────┼─────────────────┼─────────────────┤
   ___               ___               ___               ___               ___                                 ___               ___               ___                               ___               ___               ___                                 ___               ___               ___               ___               ___   
//╰─────────────────┴─────────────────┴─────────────────┴─────────────────┴─────────────────┴─────────────────┴─────────────────┴─────────────────┴─────────────────╯╰─────╯ ╰─────╯╰─────────────────┴─────────────────┴─────────────────┴─────────────────┴─────────────────┴─────────────────┴─────────────────┴─────────────────┴─────────────────╯
)

//╭─────────────────┬─────────────────┬─────────────────┬─────────────────┬─────────────────┬─────────────────┬─────────────────┬─────────────────┬─────────────────╮╭─────╮ ╭─────╮╭─────────────────┬─────────────────┬─────────────────┬─────────────────┬─────────────────┬─────────────────┬─────────────────┬─────────────────┬─────────────────╮
//         0                 1                 2                 3                 4                 5                 6                                                                                                         7                 8                 9                 10               11                 12               13
//├─────────────────┼─────────────────┼─────────────────┼─────────────────┼─────────────────┼─────────────────┼─────────────────┼─────────────────┼─────────────────┤├─────┤ ├─────┤├─────────────────┼─────────────────┼─────────────────┼─────────────────┼─────────────────┼─────────────────┼─────────────────┼─────────────────┼─────────────────┤
//        14                15                16                17                18                19                20                                                                                                        21                22                23                 24               25                 26               27
//├─────────────────┼─────────────────┼─────────────────┼─────────────────┼─────────────────┼─────────────────┼─────────────────┼─────────────────┼─────────────────┤├─────┤ ├─────┤├─────────────────┼─────────────────┼─────────────────┼─────────────────┼─────────────────┼─────────────────┼─────────────────┼─────────────────┼─────────────────┤
//        28                29                30                31                32                33                34                35                36            37     38           39                40                41                42                43                 44               45                 46               47
//├─────────────────┼─────────────────┼─────────────────┼─────────────────┼─────────────────┼─────────────────┼─────────────────┼─────────────────┼─────────────────┤├─────┤ ├─────┤├─────────────────┼─────────────────┼─────────────────┼─────────────────┼─────────────────┼─────────────────┼─────────────────┼─────────────────┼─────────────────┤
//        48                49                50                51                52                53                54                55                56            57     58           59                60                61                62                63                 64               65                 66               67 
//├─────────────────┼─────────────────┼─────────────────┼─────────────────┼─────────────────┼─────────────────┼─────────────────┼─────────────────┼─────────────────┤├─────┤ ├─────┤├─────────────────┼─────────────────┼─────────────────┼─────────────────┼─────────────────┼─────────────────┼─────────────────┼─────────────────┼─────────────────┤
//        68                69                70                71                72                                  73                74                75                                76                77                78                                  79                 80               81                 82               83
//╰─────────────────┴─────────────────┴─────────────────┴─────────────────┴─────────────────┴─────────────────┴─────────────────┴─────────────────┴─────────────────╯╰─────╯ ╰─────╯╰─────────────────┴─────────────────┴─────────────────┴─────────────────┴─────────────────┴─────────────────┴─────────────────┴─────────────────┴─────────────────╯


